# CY8C5888LTI_LP097 register map
File version: 0.1
CY8C58LP
Registers are 8-bit, read-write, no defined reset value unless marked. A register's access mark holds for its fields unless they carry their own. Offsets are from the block's base; lines under a group give offsets from that group; [hi:lo] are bit positions; {n}, {i} and the like mark numbered series; 'fields as' and 'values as' point back to an identical list; <NAME> marks a mode.

## Memory map
0x00000000 I2C
0x00000000 UART
0x40006460 via8bits1_P1_stat
0x40006461 via8bits1_Stat
0x40006462 LCD_gnome_B_reg
0x40006463 via8bits2_Stat
0x40006466 LCD_gnome_A_reg
0x40006468 via8bits2_P1_stat
0x40006470 via8bits1_P1_ctrl
0x40006474 via8bits1_gnome_res
0x40006475 via8bits1_Ctrl
0x40006476 via8bits1_P0_ctrl
0x40006478 via8bits2_P1_ctrl
0x40006565 via8bits2_P0_stat
0x40006566 via8bits1_P0_stat
0x40006575 via8bits2_P0_ctrl
0x4000657B via8bits2_Ctrl

## LCD_gnome_B_reg
Base 0x40006462
0x00 LCD_gnome_B_reg_STATUS_REG
0x20 LCD_gnome_B_reg_MASK_REG
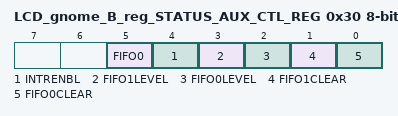
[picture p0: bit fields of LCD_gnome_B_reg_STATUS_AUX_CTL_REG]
0x30 LCD_gnome_B_reg_STATUS_AUX_CTL_REG
  [5] FIFO0 — FIFO0 clear
    1=ENABLED (Enable counter); 0=DISABLED (Disable counter)
  [4] INTRENBL — Enables or disables the Interrupt
    1=ENABLED (Interrupt enabled); 0=DISABLED (Interrupt disabled)
  [3] FIFO1LEVEL — FIFO level
    1=ENABLED (FIFO LVL: input mode: FIFO at least 1/2 empty; output mode: FIFO at least 1/2 full); 0=DISABLED (FIFO LVL: input mode: FIFO not full; output mode: FIFO not empty)
  [2] FIFO0LEVEL — FIFO level
    values as FIFO1LEVEL
  [1] FIFO1CLEAR — FIFO clear
    1=ENABLED (Clear FIFO state); 0=DISABLED (Normal FIFO operation)
  [0] FIFO0CLEAR — FIFO clear
    values as FIFO1CLEAR

## LCD_gnome_A_reg
Base 0x40006466
Registers as LCD_gnome_B_reg (with LCD_gnome_B_reg read as LCD_gnome_A_reg).

## via8bits2_P1_stat
Base 0x40006468
Registers as LCD_gnome_B_reg (with LCD_gnome_B_reg read as via8bits2_P1_stat).

## via8bits2_Stat
Base 0x40006463
Registers as LCD_gnome_B_reg (with LCD_gnome_B_reg read as via8bits2_Stat).

## via8bits2_P0_stat
Base 0x40006565
Registers as LCD_gnome_B_reg (with LCD_gnome_B_reg read as via8bits2_P0_stat).

## via8bits1_P1_stat
Base 0x40006460
Registers as LCD_gnome_B_reg (with LCD_gnome_B_reg read as via8bits1_P1_stat).

## via8bits1_Stat
Base 0x40006461
Registers as LCD_gnome_B_reg (with LCD_gnome_B_reg read as via8bits1_Stat).

## via8bits1_P0_stat
Base 0x40006566
Registers as LCD_gnome_B_reg (with LCD_gnome_B_reg read as via8bits1_P0_stat).

## UART
Base 0x00000000
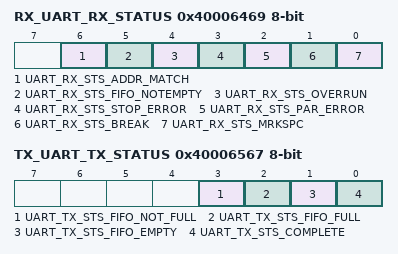
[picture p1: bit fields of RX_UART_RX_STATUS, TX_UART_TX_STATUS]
0x40006469 RX_UART_RX_STATUS — RX status register
  [6] UART_RX_STS_ADDR_MATCH ro, [5] UART_RX_STS_FIFO_NOTEMPTY ro, [4] UART_RX_STS_OVERRUN ro, [3] UART_RX_STS_STOP_ERROR ro, [2] UART_RX_STS_PAR_ERROR ro, [1] UART_RX_STS_BREAK ro, [0] UART_RX_STS_MRKSPC ro
0x4000652A RX_UART_RX_ADDRESS1 — RX Address1 Register
0x4000653A RX_UART_RX_ADDRESS2 — RX Address2 Register
0x40006547 TX_UART_TX_DATA — TX Data Register
0x4000654A RX_UART_RX_DATA — RX Data Register
0x40006567 TX_UART_TX_STATUS — TX status register
  [3] UART_TX_STS_FIFO_NOT_FULL ro, [2] UART_TX_STS_FIFO_FULL ro, [1] UART_TX_STS_FIFO_EMPTY ro, [0] UART_TX_STS_COMPLETE ro

## via8bits2_Ctrl
Base 0x4000657B
0x00 via8bits2_Ctrl_CONTROL_REG

## via8bits2_P0_ctrl
Base 0x40006575
Registers as via8bits2_Ctrl (with via8bits2_Ctrl read as via8bits2_P0_ctrl).

## via8bits2_P1_ctrl
Base 0x40006478
Registers as via8bits2_Ctrl (with via8bits2_Ctrl read as via8bits2_P1_ctrl).

## via8bits1_gnome_res
Base 0x40006474
Registers as via8bits2_Ctrl (with via8bits2_Ctrl read as via8bits1_gnome_res).

## via8bits1_Ctrl
Base 0x40006475
Registers as via8bits2_Ctrl (with via8bits2_Ctrl read as via8bits1_Ctrl).

## via8bits1_P0_ctrl
Base 0x40006476
Registers as via8bits2_Ctrl (with via8bits2_Ctrl read as via8bits1_P0_ctrl).

## via8bits1_P1_ctrl
Base 0x40006470
Registers as via8bits2_Ctrl (with via8bits2_Ctrl read as via8bits1_P1_ctrl).
